# A31G33x register map
Vendor: VENDOR ABOV Semiconductor Co., Ltd.; Series: A31G33x; File version: 1.0
CPU: CM0+ r0p1, little endian, no MPU, no FPU, VTOR, 2 interrupt priority bits
Registers are 32-bit, read-only, no defined reset value unless marked. A register's access mark holds for its fields unless they carry their own. Offsets are from the block's base; [hi:lo] are bit positions.

## SCUCC — System Control Unit: Chip Configuration
Base 0x4000F000
0x00 VENDORID reset 0x41424F56 — Vendor Identification Register
  [31:0] VENDID — Vendor Identification
0x04 CHIPID reset 0x47313360 (reset mask 0xFFFFFFF0) — Chip Identification Register
  [31:0] CHIPID — Chip Identification
0x08 REVNR reset 0x0 (reset mask 0xFFFFFF00) — Revision Number Register
  [7:0] REVNO — Chip Revision Number
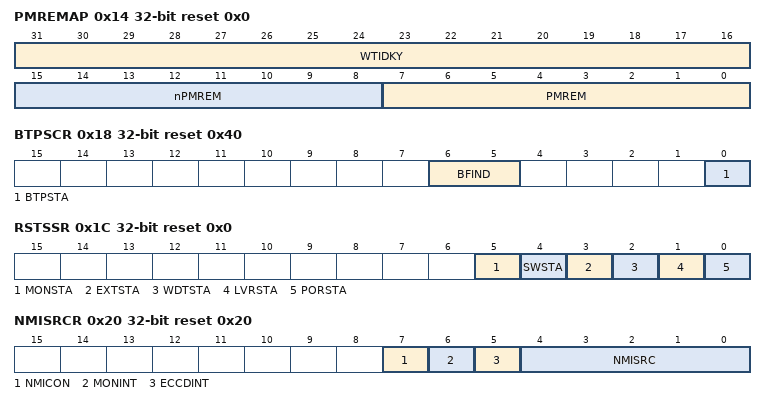
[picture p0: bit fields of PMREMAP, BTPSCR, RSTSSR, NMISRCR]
0x14 PMREMAP rw reset 0x0 — Program Memory Remap Register
  [31:16] WTIDKY wo — Write Identification Key (0xe2f1)
    0xE2F1=Value (Key Value (0xe2f1))
  [15:8] nPMREM wo — Write Complement Key
    150=Boot ROM is re-mapped to address 0x0. (0x96); 0=Flash Memory is re-mapped to address 0x0
  [7:0] PMREM — Program Memory Remap
    105=Boot ROM is re-mapped to address 0x0. (0x69); 0=Flash Memory is re-mapped to address 0x0
0x18 BTPSCR rw reset 0x40 (reset mask 0xFFFFFFDE) — Boot Pin Status and Control Register
  [6:5] BFIND — BOOT Pin Function Indicator
    2=PORorEXTR (Check the BOOT pin when a system reset occurs by nRESET including POR.); 3=POR (Check the BOOT pin when a system reset occurs only by POR.)
  [0] BTPSTA ro — BOOT Pin Status
    0=Low (The BOOT pin is low level.); 1=High (The BOOT pin is high level.)
0x1C RSTSSR rw reset 0x0 (reset mask 0xFFFFFFC0) — Reset Source Status Register
  [5] MONSTA — Clock Monitoring Reset Status
    0=NotDetected; 1=Detected (CMR was detected.)
  [4] SWSTA — Software Reset Status
    0=NotDetected; 1=Detected (SWR was detected.)
  [3] EXTSTA — External Pin Reset Status
    0=NotDetected; 1=Detected (EXTR was detected.)
  [2] WDTSTA — Watch-Dog Timer Reset Status
    0=NotDetected; 1=Detected (WDTR was detected.)
  [1] LVRSTA — LVR Reset Status
    0=NotDetected; 1=Detected (LVR was detected.)
  [0] PORSTA — POR Reset Status
    0=NotDetected; 1=Detected (POR was detected.)
0x20 NMISRCR rw reset 0x20 — NMI Source Selection Register
  [7] NMICON — Non-Maskable Interrupt (NMI) Control
    0=Disable NMI; 1=Enable NMI
  [6] MONINT — Clock Monitoring Interrupt Selection
    0=NotSelect (Non-select clock monitoring interrupt for NMI source.); 1=Select clock monitoring interrupt for NMI source
  [5] ECCDINT — ECC Detection Interrupt Selection
    0=NotSelect (Non-select ECC detection interrupt for NMI source.); 1=Select ECC detection interrupt for NMI source
  [4:0] NMISRC — Non-Maskable Interrupt Source Selection
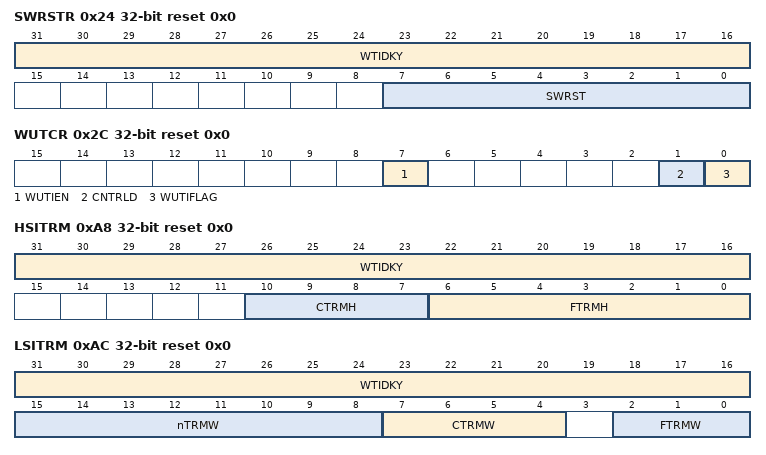
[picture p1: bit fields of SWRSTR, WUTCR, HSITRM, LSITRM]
0x24 SWRSTR wo reset 0x0 — Software Reset Register
  [31:16] WTIDKY — Write Identification Key (0x9eb3)
    0x9EB3=Value (Key Value (0x9eb3))
  [7:0] SWRST — Software Reset (System Reset)
    45=Generate (A software reset will be generated for all peripheral and core. (0x2d)); 0=NoEffect
0x28 SRSTVR reset 0x55 — System Reset Validation Register
  [7:0] VALID — System Reset Validation
0x2C WUTCR rw reset 0x0 — Wake-Up Timer Control Register
  [7] WUTIEN — Wake-Up Timer Interrupt Enable
    0=Disable Wake-Up Timer interrupt; 1=Enable Wake-Up Timer interrupt
  [1] CNTRLD — Counter Reload
    0=NoEffect; 1=Reload data to counter
  [0] WUTIFLAG — Wake-Up Timer Interrupt Flag
    0=No request occurred; 1=Request occurred
0x30 WUTDR rw reset 0xFA — Wake-Up Timer Data Register
  [15:0] WUTDATA — Wake-Up Timer Data
0xA8 HSITRM rw reset 0x0 (reset mask 0xFFFFF800) — High Speed Internal RC Trim Register (HSICNFIG)
  [31:16] WTIDKY wo — Write Identification Key (0xa6b5)
    0xA6B5=Value (Key Value (0xa6b5))
  [10:7] CTRMH — Factory HSI Coarse Trim
  [6:0] FTRMH — Factory HSI Fine Trim
0xAC LSITRM rw reset 0x0 (reset mask 0xFFFFFF08) — Low Speed Internal RC Trim Register (LSICNFIG)
  [31:16] WTIDKY wo — Write Identification Key (0x4c3d)
    0x4C3D=Value (Key Value (0x4c3d))
  [15:8] nTRMW wo — Write Complement Key
  [7:4] CTRMW — Factory LSI Coarse Trim
  [2:0] FTRMW — Factory LSI Fine Trim

## Notices in the file
Copyright (C) 2012 ARM Limited. All rights reserved.
Purpose: System Viewer Description (SVD) Example (Schema Version 1.1)
This is a description of a none-existent and incomplete device
for demonstration purposes only.
Redistribution and use in source and binary forms, with or without
modification, are permitted provided that the following conditions are met:
- Redistributions of source code must retain the above copyright
notice, this list of conditions and the following disclaimer.
- Redistributions in binary form must reproduce the above copyright
notice, this list of conditions and the following disclaimer in the
documentation and/or other materials provided with the distribution.
- Neither the name of ARM nor the names of its contributors may be used
to endorse or promote products derived from this software without
specific prior written permission.
THIS SOFTWARE IS PROVIDED BY THE COPYRIGHT HOLDERS AND CONTRIBUTORS "AS IS"
AND ANY EXPRESS OR IMPLIED WARRANTIES, INCLUDING, BUT NOT LIMITED TO, THE
IMPLIED WARRANTIES OF MERCHANTABILITY AND FITNESS FOR A PARTICULAR PURPOSE
ARE DISCLAIMED. IN NO EVENT SHALL COPYRIGHT HOLDERS AND CONTRIBUTORS BE
LIABLE FOR ANY DIRECT, INDIRECT, INCIDENTAL, SPECIAL, EXEMPLARY, OR
CONSEQUENTIAL DAMAGES (INCLUDING, BUT NOT LIMITED TO, PROCUREMENT OF
SUBSTITUTE GOODS OR SERVICES; LOSS OF USE, DATA, OR PROFITS; OR BUSINESS
INTERRUPTION) HOWEVER CAUSED AND ON ANY THEORY OF LIABILITY, WHETHER IN
CONTRACT, STRICT LIABILITY, OR TORT (INCLUDING NEGLIGENCE OR OTHERWISE)
ARISING IN ANY WAY OUT OF THE USE OF THIS SOFTWARE, EVEN IF ADVISED OF THE
POSSIBILITY OF SUCH DAMAGE.
